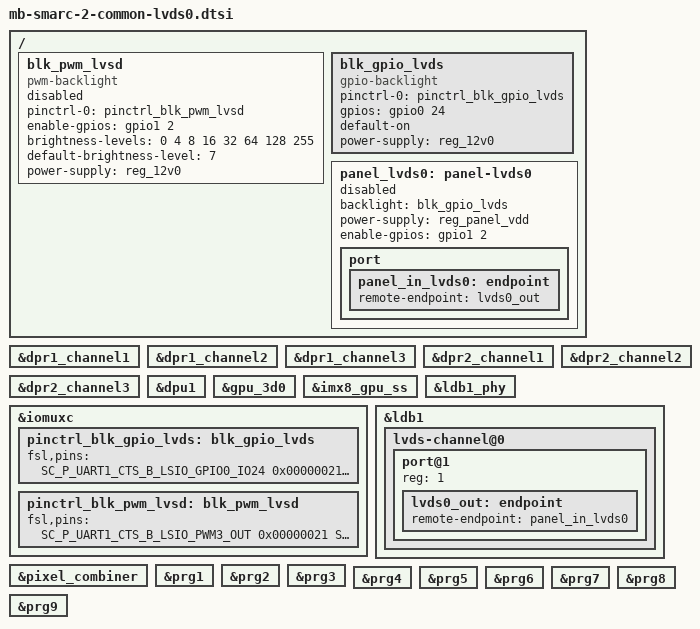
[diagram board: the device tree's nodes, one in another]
/*
 * Copyright 2018-2019 TQ Systems GmbH
 *
 * This program is free software; you can redistribute it and/or
 * modify it under the terms of the GNU General Public License
 * as published by the Free Software Foundation; either version 2
 * of the License, or (at your option) any later version.
 *
 * This program is distributed in the hope that it will be useful,
 * but WITHOUT ANY WARRANTY; without even the implied warranty of
 * MERCHANTABILITY or FITNESS FOR A PARTICULAR PURPOSE.  See the
 * GNU General Public License for more details.
 */

/ {
	blk_pwm_lvsd: blk_pwm_lvsd {
		compatible = "pwm-backlight";
		pinctrl-names = "default" ;
		pinctrl-0 = <&pinctrl_blk_pwm_lvsd>;
		/* should be <&pwm3_xxx> */
		/*pwms = <&pwm_adma_lcdif 0 5000000>;*/
		enable-gpios = <&gpio1 2 GPIO_ACTIVE_HIGH>;
		brightness-levels = <0 4 8 16 32 64 128 255>;
		default-brightness-level = <7>;
		power-supply = <&reg_12v0>;
		status = "disabled";
	};

	/* TODO: use pwm backlight as soon as drivers are available */
	blk_gpio_lvds: blk_gpio_lvds {
		compatible = "gpio-backlight";
		pinctrl-names = "default";
		pinctrl-0 = <&pinctrl_blk_gpio_lvds>;
		gpios = <&gpio0 24 GPIO_ACTIVE_HIGH>;
		default-on;
		power-supply = <&reg_12v0>;
		status = "okay";
	};

	panel_lvds0: panel-lvds0 {
		backlight = <&blk_gpio_lvds>;
		power-supply = <&reg_panel_vdd>;
		/* TODO enable-backlight should be done by pwm */
		enable-gpios = <&gpio1 2 GPIO_ACTIVE_HIGH>;
		status = "disabled";

		port {
			panel_in_lvds0: endpoint {
				remote-endpoint = <&lvds0_out>;
			};
		};
	};
};

&dpr1_channel1 {
	status = "okay";
};

&dpr1_channel2 {
	status = "okay";
};

&dpr1_channel3 {
	status = "okay";
};

&dpr2_channel1 {
	status = "okay";
};

&dpr2_channel2 {
	status = "okay";
};

&dpr2_channel3 {
	status = "okay";
};

&dpu1 {
	status = "okay";
};

&gpu_3d0 {
	status = "okay";
};

&imx8_gpu_ss {
	status = "okay";
};

&iomuxc {

	pinctrl_blk_gpio_lvds: blk_gpio_lvds {
		fsl,pins = <
			SC_P_UART1_CTS_B_LSIO_GPIO0_IO24	0x00000021
			SC_P_SPI2_SDI_LSIO_GPIO1_IO02		0x00000021
		>;
	};

	pinctrl_blk_pwm_lvsd: blk_pwm_lvsd {
		fsl,pins = <
			/* TODO: add pwm3_xxx to fsl device tree (like "pwm_adma_lcdif" in fsl-imx8dx.dtsi )*/ 
			SC_P_UART1_CTS_B_LSIO_PWM3_OUT	0x00000021
			SC_P_SPI2_SDI_LSIO_GPIO1_IO02	0x00000021
		>;
	};

};

&ldb1_phy {
	status = "okay";
};

&ldb1 {
	status = "okay";

	lvds-channel@0 {
		status = "okay";

		port@1 {
			reg = <1>;

			lvds0_out: endpoint {
				remote-endpoint = <&panel_in_lvds0>;
			};
		};
	};
};

&pixel_combiner {
	status = "okay";
};

&prg1 {
	status = "okay";
};

&prg2 {
	status = "okay";
};

&prg3 {
	status = "okay";
};

&prg4 {
	status = "okay";
};

&prg5 {
	status = "okay";
};

&prg6 {
	status = "okay";
};

&prg7 {
	status = "okay";
};

&prg8 {
	status = "okay";
};

&prg9 {
	status = "okay";
};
